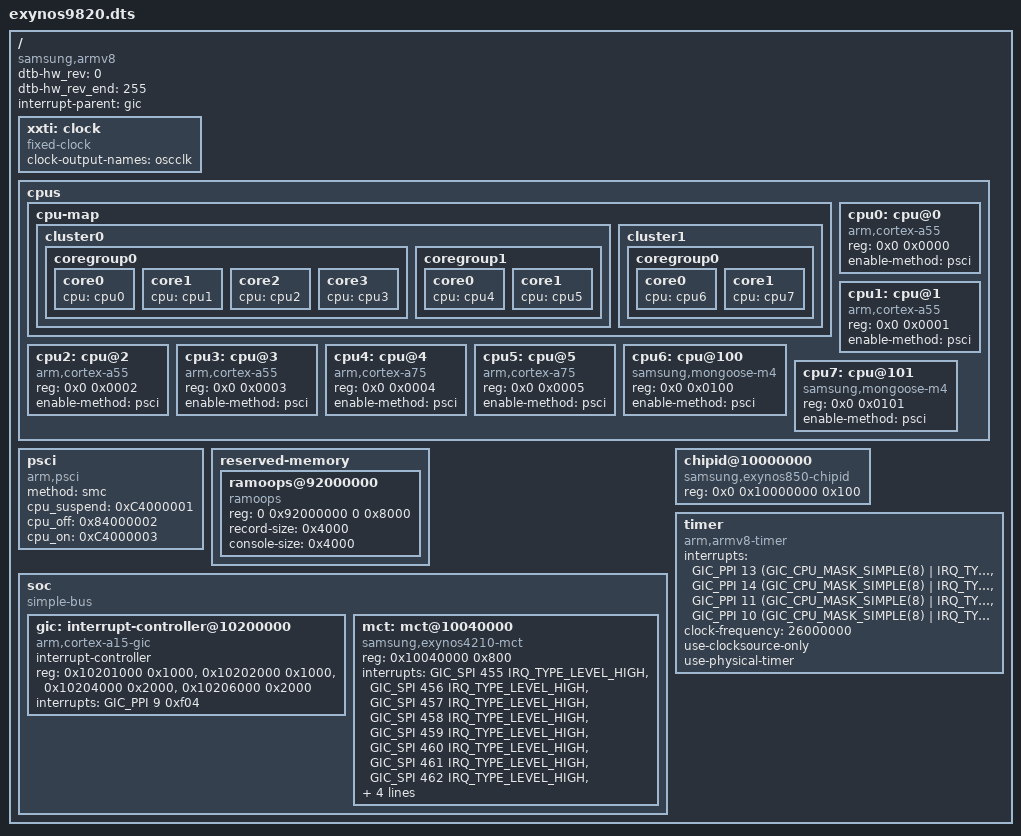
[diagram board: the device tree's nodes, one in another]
/*
 * SAMSUNG EXYNOS9820 SoC device tree source
 *
 * Copyright (c) 2018 Samsung Electronics Co., Ltd.
 *             http://www.samsung.com
 *
 * SAMSUNG EXYNOS9820 SoC device nodes are listed in this file.
 * EXYNOS based board files can include this file and provide
 * values for board specfic bindings.
 *
 * This program is free software; you can redistribute it and/or modify
 * it under the terms of the GNU General Public License version 2 as
 * published by the Free Software Foundation.
 */

/dts-v1/;
#include <dt-bindings/interrupt-controller/arm-gic.h>

#include "exynos9820-pinctrl.dtsi"

/ {
	compatible = "samsung,armv8", "samsung,exynos9820";
	dtb-hw_rev = <0>;
	dtb-hw_rev_end = <255>;

	interrupt-parent = <&gic>;
	#address-cells = <2>;
	#size-cells = <1>;

	xxti: clock {
		/* XXTI */
		compatible = "fixed-clock";
		clock-output-names = "oscclk";
		#clock-cells = <0>;
	};

	cpus {
		#address-cells = <2>;
		#size-cells = <0>;

		cpu-map {
			cluster0 {
				coregroup0 {
					core0 {
						cpu = <&cpu0>;
					};
					core1 {
						cpu = <&cpu1>;
					};
					core2 {
						cpu = <&cpu2>;
					};
					core3 {
						cpu = <&cpu3>;
					};
				};

				coregroup1 {
					core0 {
						cpu = <&cpu4>;
					};
					core1 {
						cpu = <&cpu5>;
					};
				};
			};

			cluster1 {
				coregroup0 {
					core0 {
						cpu = <&cpu6>;
					};
					core1 {
						cpu = <&cpu7>;
					};
				};
			};

		};

		cpu0: cpu@0 {
			device_type = "cpu";
			compatible = "arm,cortex-a55", "arm,armv8";
			reg = <0x0 0x0000>;
			enable-method = "psci";
		};

		cpu1: cpu@1 {
			device_type = "cpu";
			compatible = "arm,cortex-a55", "arm,armv8";
			reg = <0x0 0x0001>;
			enable-method = "psci";
		};

		cpu2: cpu@2 {
			device_type = "cpu";
			compatible = "arm,cortex-a55", "arm,armv8";
			reg = <0x0 0x0002>;
			enable-method = "psci";
		};

		cpu3: cpu@3 {
			device_type = "cpu";
			compatible = "arm,cortex-a55", "arm,armv8";
			reg = <0x0 0x0003>;
			enable-method = "psci";
		};

		cpu4: cpu@4 {
			device_type = "cpu";
			compatible = "arm,cortex-a75", "arm,armv8";
			reg = <0x0 0x0004>;
			enable-method = "psci";
		};

		cpu5: cpu@5 {
			device_type = "cpu";
			compatible = "arm,cortex-a75", "arm,armv8";
			reg = <0x0 0x0005>;
			enable-method = "psci";
		};

		cpu6: cpu@100 {
			device_type = "cpu";
			compatible = "samsung,mongoose-m4", "arm,armv8";
			reg = <0x0 0x0100>;
			enable-method = "psci";
		};

		cpu7: cpu@101 {
			device_type = "cpu";
			compatible = "samsung,mongoose-m4", "arm,armv8";
			reg = <0x0 0x0101>;
			enable-method = "psci";
		};
	};

	psci {
		compatible = "arm,psci";
		method = "smc";
		cpu_suspend = <0xC4000001>;
		cpu_off = <0x84000002>;
		cpu_on = <0xC4000003>;
	};

	reserved-memory {
		#address-cells = <2>;
		#size-cells = <2>;
		ranges;

		ramoops@92000000 {
			compatible = "ramoops";
			reg = <0 0x92000000 0 0x8000>;
			record-size = <0x4000>;
			console-size = <0x4000>;
		};
	};

	soc: soc {
		compatible = "simple-bus";
		#address-cells = <1>;
		#size-cells = <1>;
		ranges = <0 0 0 0x18000000>;

		gic: interrupt-controller@10200000 {
			compatible = "arm,cortex-a15-gic";
			#interrupt-cells = <3>;
			interrupt-controller;
			reg = <0x10201000 0x1000>,
			      <0x10202000 0x1000>,
			      <0x10204000 0x2000>,
			      <0x10206000 0x2000>;
			interrupts = <GIC_PPI 9 0xf04>;
		};

		mct: mct@10040000 {
			compatible = "samsung,exynos4210-mct";
			reg = <0x10040000 0x800>;
			interrupts = <GIC_SPI 455 IRQ_TYPE_LEVEL_HIGH>,
				<GIC_SPI 456 IRQ_TYPE_LEVEL_HIGH>,
				<GIC_SPI 457 IRQ_TYPE_LEVEL_HIGH>,
				<GIC_SPI 458 IRQ_TYPE_LEVEL_HIGH>,
				<GIC_SPI 459 IRQ_TYPE_LEVEL_HIGH>,
				<GIC_SPI 460 IRQ_TYPE_LEVEL_HIGH>,
				<GIC_SPI 461 IRQ_TYPE_LEVEL_HIGH>,
				<GIC_SPI 462 IRQ_TYPE_LEVEL_HIGH>,
				<GIC_SPI 463 IRQ_TYPE_LEVEL_HIGH>,
				<GIC_SPI 464 IRQ_TYPE_LEVEL_HIGH>,
				<GIC_SPI 465 IRQ_TYPE_LEVEL_HIGH>,
				<GIC_SPI 466 IRQ_TYPE_LEVEL_HIGH>;

			// TODO clocks
			//clocks = <&xxti>, <&cmu_peris CLK_PCLK_MCT>;
			//clock-names = "fin_pll", "mct";
		};
	};

	chipid@10000000 {
		compatible = "samsung,exynos850-chipid";
		reg = <0x0 0x10000000 0x100>;
	};

	timer {
	        compatible = "arm,armv8-timer";
		interrupts = <GIC_PPI 13
				(GIC_CPU_MASK_SIMPLE(8) | IRQ_TYPE_LEVEL_LOW)>,
			     <GIC_PPI 14
				(GIC_CPU_MASK_SIMPLE(8) | IRQ_TYPE_LEVEL_LOW)>,
			     <GIC_PPI 11
				(GIC_CPU_MASK_SIMPLE(8) | IRQ_TYPE_LEVEL_LOW)>,
			     <GIC_PPI 10
				(GIC_CPU_MASK_SIMPLE(8) | IRQ_TYPE_LEVEL_LOW)>;
	        clock-frequency = <26000000>;
		use-clocksource-only;
		use-physical-timer;
	};
};
